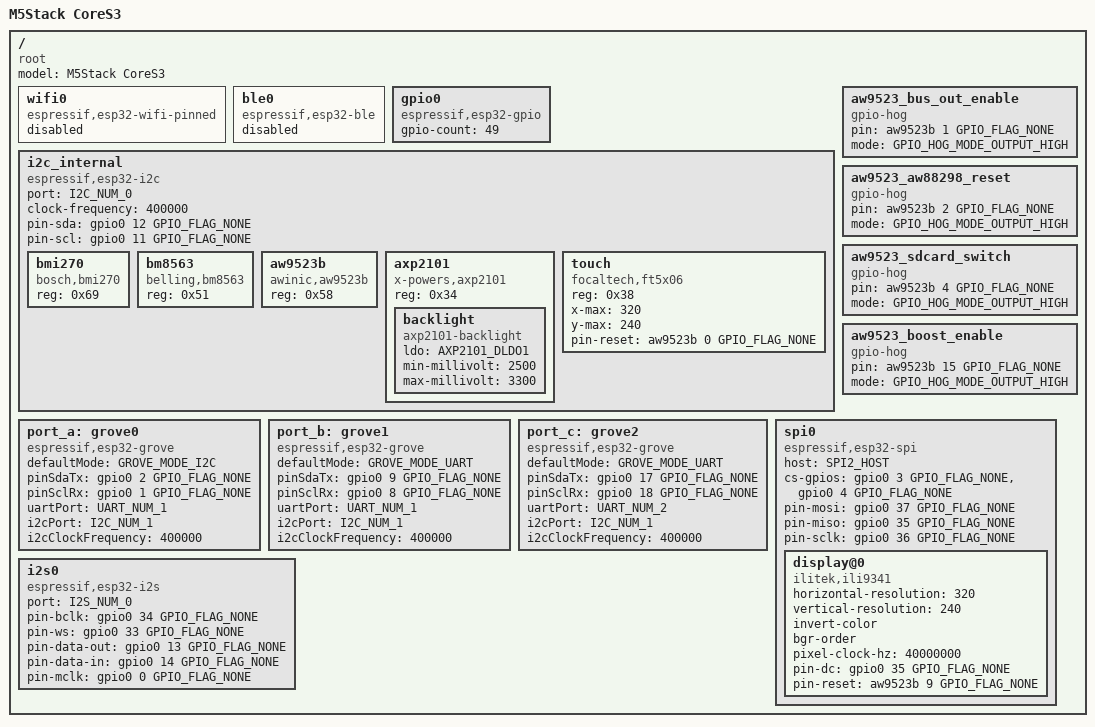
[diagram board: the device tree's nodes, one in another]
/dts-v1/;

#include <tactility/bindings/root.h>
#include <tactility/bindings/esp32_ble.h>
#include <tactility/bindings/esp32_wifi_pinned.h>
#include <tactility/bindings/esp32_gpio.h>
#include <tactility/bindings/esp32_grove.h>
#include <tactility/bindings/esp32_i2c.h>
#include <tactility/bindings/esp32_i2s.h>
#include <tactility/bindings/esp32_spi.h>
#include <tactility/bindings/esp32_uart.h>
#include <bindings/bmi270.h>
#include <bindings/bm8563.h>
#include <bindings/axp2101.h>
#include <bindings/axp2101_backlight.h>
#include <bindings/aw9523b.h>
#include <bindings/ft5x06.h>
#include <bindings/ili9341.h>
#include <tactility/bindings/esp32_sdspi.h>
#include <tactility/bindings/gpio_hog.h>

// SD card is not supported because of a hardware problem:
// The display uses pin 35 as input (MISO), but the SPI bus (and SD card) uses the same pin as DC (output).

// Reference: https://docs.m5stack.com/en/core/CoreS3
/ {
	compatible = "root";
	model = "M5Stack CoreS3";

	wifi0 {
		compatible = "espressif,esp32-wifi-pinned";
		status = "disabled";
	};

	ble0 {
		compatible = "espressif,esp32-ble";
		status = "disabled";
	};

	gpio0 {
		compatible = "espressif,esp32-gpio";
		gpio-count = <49>;
	};

	i2c_internal {
		compatible = "espressif,esp32-i2c";
		port = <I2C_NUM_0>;
		clock-frequency = <400000>;
		pin-sda = <&gpio0 12 GPIO_FLAG_NONE>;
		pin-scl = <&gpio0 11 GPIO_FLAG_NONE>;

		bmi270 {
			compatible = "bosch,bmi270";
			reg = <0x69>;
		};

		bm8563 {
			compatible = "belling,bm8563";
			reg = <0x51>;
		};

		// P0_0 = touch reset, P0_1 = bus-out enable, P0_2 = AW88298 reset,
		// P0_4 = SD card switch, P1_1 = LCD reset, P1_7 = boost enable (SY7088)
		aw9523b: aw9523b {
			compatible = "awinic,aw9523b";
			reg = <0x58>;
		};

		axp2101: axp2101 {
			compatible = "x-powers,axp2101";
			reg = <0x34>;

			// LCD backlight (DLDO1). Raw register codes [20,28] map to [2500,3300]mV;
			// below 2500mV the backlight was considered "too dark" to be useful.
			backlight {
				compatible = "axp2101-backlight";
				ldo = <AXP2101_DLDO1>;
				min-millivolt = <2500>;
				max-millivolt = <3300>;
			};
		};

		touch {
			compatible = "focaltech,ft5x06";
			reg = <0x38>;
			x-max = <320>;
			y-max = <240>;
			pin-reset = <&aw9523b 0 GPIO_FLAG_NONE>;
		};
	};

	// Bus-out enable, AW88298 (audio amp) reset, SD card power switch and boost enable
	// (SY7088) are AW9523B pins with no owning peripheral driver yet.
	aw9523_bus_out_enable {
		compatible = "gpio-hog";
		pin = <&aw9523b 1 GPIO_FLAG_NONE>;
		mode = <GPIO_HOG_MODE_OUTPUT_HIGH>;
	};

	aw9523_aw88298_reset {
		compatible = "gpio-hog";
		pin = <&aw9523b 2 GPIO_FLAG_NONE>;
		mode = <GPIO_HOG_MODE_OUTPUT_HIGH>;
	};

	aw9523_sdcard_switch {
		compatible = "gpio-hog";
		pin = <&aw9523b 4 GPIO_FLAG_NONE>;
		mode = <GPIO_HOG_MODE_OUTPUT_HIGH>;
	};

	aw9523_boost_enable {
		compatible = "gpio-hog";
		pin = <&aw9523b 15 GPIO_FLAG_NONE>;
		mode = <GPIO_HOG_MODE_OUTPUT_HIGH>;
	};

	port_a: grove0 {
		compatible = "espressif,esp32-grove";
		defaultMode = <GROVE_MODE_I2C>;
		pinSdaTx = <&gpio0 2 GPIO_FLAG_NONE>;
		pinSclRx = <&gpio0 1 GPIO_FLAG_NONE>;
		uartPort = <UART_NUM_1>;
		i2cPort = <I2C_NUM_1>;
		i2cClockFrequency = <400000>;
	};

	port_b: grove1 {
		compatible = "espressif,esp32-grove";
		defaultMode = <GROVE_MODE_UART>;
		pinSdaTx = <&gpio0 9 GPIO_FLAG_NONE>;
		pinSclRx = <&gpio0 8 GPIO_FLAG_NONE>;
		uartPort = <UART_NUM_1>;
		i2cPort = <I2C_NUM_1>;
		i2cClockFrequency = <400000>;
	};

	port_c: grove2 {
		compatible = "espressif,esp32-grove";
		defaultMode = <GROVE_MODE_UART>;
		pinSdaTx = <&gpio0 17 GPIO_FLAG_NONE>;
		pinSclRx = <&gpio0 18 GPIO_FLAG_NONE>;
		uartPort = <UART_NUM_2>;
		i2cPort = <I2C_NUM_1>;
		i2cClockFrequency = <400000>;
	};

	spi0 {
		compatible = "espressif,esp32-spi";
		host = <SPI2_HOST>;
		cs-gpios = <&gpio0 3 GPIO_FLAG_NONE>, // Display
		           <&gpio0 4 GPIO_FLAG_NONE>; // SD card
		pin-mosi = <&gpio0 37 GPIO_FLAG_NONE>;
		pin-miso = <&gpio0 35 GPIO_FLAG_NONE>;
		pin-sclk = <&gpio0 36 GPIO_FLAG_NONE>;

		display@0 {
			compatible = "ilitek,ili9341";
			horizontal-resolution = <320>;
			vertical-resolution = <240>;
			invert-color;
			bgr-order;
			pixel-clock-hz = <40000000>;
			pin-dc = <&gpio0 35 GPIO_FLAG_NONE>;
			pin-reset = <&aw9523b 9 GPIO_FLAG_NONE>;
		};
	};

	// TODO: Enable speaker via ES7210 I2C: https://github.com/m5stack/M5Unified/blob/a6256725481f1bc366655fa48cf03b6095e30ad1/src/M5Unified.cpp#L417
	// TODO: Enable microphone via ES7210 I2C: https://github.com/m5stack/M5Unified/blob/a6256725481f1bc366655fa48cf03b6095e30ad1/src/M5Unified.cpp#L616
	i2s0 {
		// Note: M5Unified sets the following for speaker: magnification = 2, oversampling = 1
		// Note: M5Unified sets the following for microphone: magnification = 4
		compatible = "espressif,esp32-i2s";
		port = <I2S_NUM_0>;
		pin-bclk = <&gpio0 34 GPIO_FLAG_NONE>;
		pin-ws = <&gpio0 33 GPIO_FLAG_NONE>;
		pin-data-out = <&gpio0 13 GPIO_FLAG_NONE>;
		pin-data-in = <&gpio0 14 GPIO_FLAG_NONE>;
		pin-mclk = <&gpio0 0 GPIO_FLAG_NONE>;
	};
};
